# GD32A72_A74x register map
File version: 1.0
CPU: CM7 r2p1, little endian, MPU, FPU, DSP, 4 interrupt priority bits
Registers are 32-bit, read-write, reset 0x0 unless marked. A register's access mark holds for its fields unless they carry their own. Offsets are from the block's base; [hi:lo] are bit positions; {n}, {i} and the like mark numbered series; 'fields as' and 'values as' point back to an identical list.

## GPIOA — General-purpose and alternate-function I/Os
Base 0x48000000
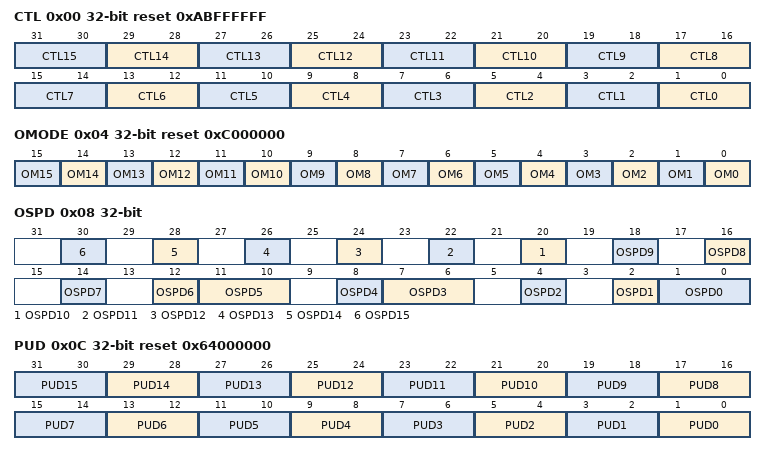
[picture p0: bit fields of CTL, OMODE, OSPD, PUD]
0x00 CTL reset 0xABFFFFFF — Port control register
  [2n+1:2n] CTL{n} (n=0..15) — Pin {n} configuration bits
0x04 OMODE reset 0xC000000 — Port output mode register
  [n] OM{n} (n=0..15) — Pin {n} output mode bit
0x08 OSPD — Port output speed register
  [2n] OSPD{n} (n=6..15) — Pin {n} output max speed bits
  [11:10] OSPD5 — Pin 5 output max speed bits
  [8] OSPD4 — Pin 4 output max speed bits
  [7:6] OSPD3 — Pin 3 output max speed bits
  [4] OSPD2 — Pin 2 output max speed bits
  [2] OSPD1 — Pin 1 output max speed bits
  [1:0] OSPD0 — Pin 0 output max speed bits
0x0C PUD reset 0x64000000 — Port pull-up / down register
  [2n+1:2n] PUD{n} (n=0..15) — Pin {n} pull-up or pull-down bits
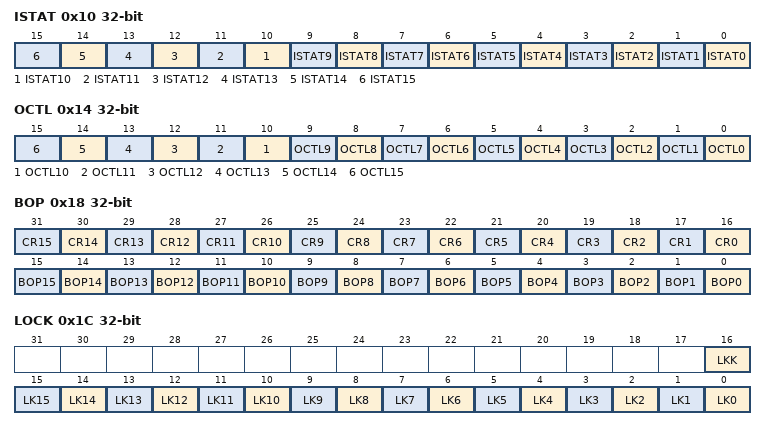
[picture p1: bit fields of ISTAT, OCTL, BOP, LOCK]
0x10 ISTAT ro — Port input status register
  [n] ISTAT{n} (n=0..15) — Port input status {n}
0x14 OCTL — Port output control register
  [n] OCTL{n} (n=0..15) — Port output control {n}
0x18 BOP wo — Port bit operate register
  [n+16] CR{n} (n=0..15) — Port clear bit {n}
  [n] BOP{n} (n=0..15) — Port set bit {n}
0x1C LOCK — Port configuration lock register
  [16] LKK — Lock key
  [15] LK15 — LOCK key writing sequence:
  [n] LK{n} (n=0..14) — Port lock bit {n+1}
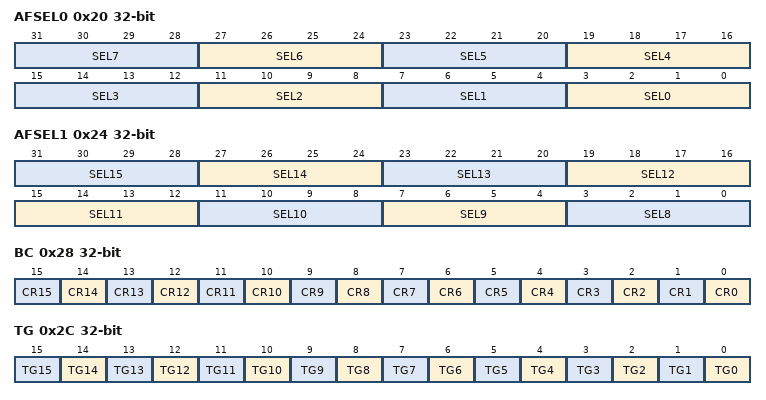
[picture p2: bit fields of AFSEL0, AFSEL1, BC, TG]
0x20 AFSEL0 — Alternate function selected register 0
  [4n+3:4n] SEL{n} (n=0..7) — Pin {n} alternate function selected
0x24 AFSEL1 — Alternate function selected register 1
  [4n-29:4n-32] SEL{n} (n=12..15) — Pin {n} alternate function selected
  [15:12] SEL11 — Pin 1 alternate function selected
  [11:8] SEL10 — Pin 10 alternate function selected
  [7:4] SEL9 — Pin 9 alternate function selected
  [3:0] SEL8 — Pin 8 alternate function selected
0x28 BC wo — Bit clear register
  [n] CR{n} (n=0..15) — Port clear bit {n}
0x2C TG wo — Port bit toggle register
  [n] TG{n} (n=0..15) — Port toggle bit {n}
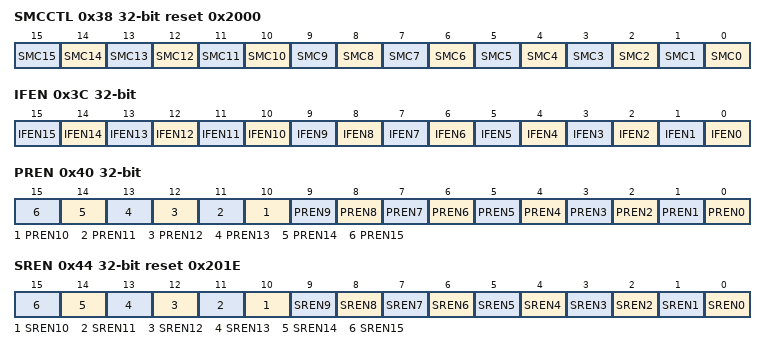
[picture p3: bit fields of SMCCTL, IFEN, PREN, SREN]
0x38 SMCCTL reset 0x2000 — Port safe mode control register
  [n] SMC{n} (n=0..15) — Pin {n} safe mode control
0x3C IFEN — Port filtering enable register
  [n] IFEN{n} (n=0..15) — Pin {n} input filter enable bit {n}
0x40 PREN — Port retain enable register
  [n] PREN{n} (n=0..15) — Pin {n} pad retain enable
0x44 SREN reset 0x201E — Port slew rate enable register
  [n] SREN{n} (n=0..15) — Pin {n} slew rate enable
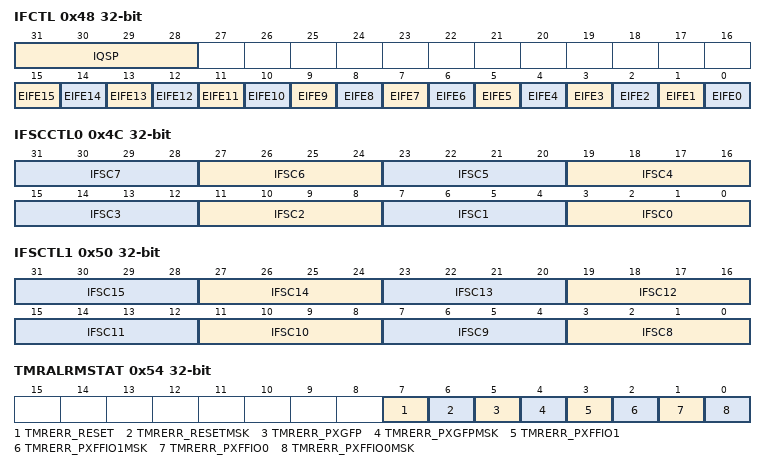
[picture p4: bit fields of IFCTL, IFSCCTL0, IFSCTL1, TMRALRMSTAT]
0x48 IFCTL — Interrupt filtering control Register
  [31:28] IQSP — External interrupt qualification sampling period for PIN0 to PIN15:
  [n] EIFE{n} (n=0..15) — Pin {n} enables digital glitch filter on the interrupt pad input
0x4C IFSCCTL0 — Interrupt filtering sample counter control register 0
  [4n+3:4n] IFSC{n} (n=0..7) — Pin{n} maximum interrupt filter counter setting
0x50 IFSCTL1 — Interrupt filtering sample counter control register 1
  [4n-29:4n-32] IFSC{n} (n=8..15) — Pin{n} maximum interrupt filter counter setting
0x54 TMRALRMSTAT — TMR alarm status register
  [7] TMRERR_RESET — RESET port mode configuration TMR error alarm
  [6] TMRERR_RESETMSK — RESET port mode configuration TMR error alarm mask
  [5] TMRERR_PXGFP — GPF port mode configuration TMR error alarm
  [4] TMRERR_PXGFPMSK — GPF port mode configuration TMR alarm error mask
  [3] TMRERR_PXFFIO1 — FFP1 port mode configuration TMR error alarm
  [2] TMRERR_PXFFIO1MSK — FFP1 port mode configuration TMR alarm error mask
  [1] TMRERR_PXFFIO0 — FFP0 port mode configuration TMR error alarm
  [0] TMRERR_PXFFIO0MSK — FFP0 port mode configuration TMR alarm mask

## GPIOB — General-purpose and alternate-function I/Os
Base 0x48000400
Registers as GPIOA; these are added or differ:
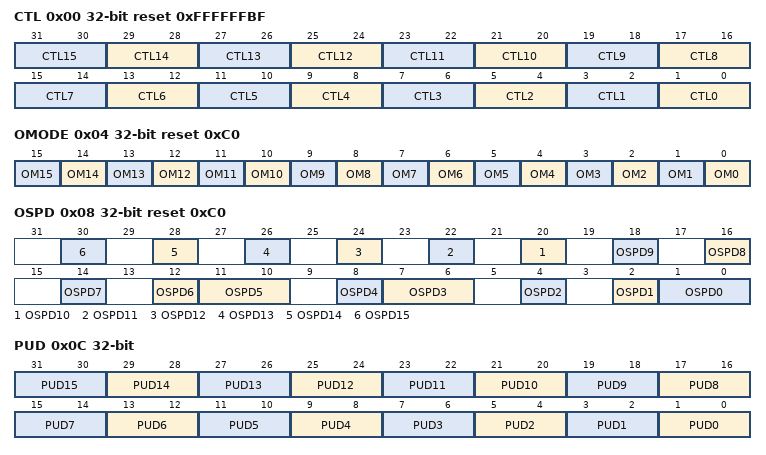
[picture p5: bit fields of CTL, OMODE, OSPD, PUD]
0x00 CTL reset 0xFFFFFFBF — Port control register
  [2n+1:2n] CTL{n} (n=0..15) — Pin {n} configuration bits
0x04 OMODE reset 0xC0 — Port output mode register
  [n] OM{n} (n=0..15) — Pin {n} output mode bit
0x08 OSPD reset 0xC0 — Port output speed register
  fields as GPIOA.OSPD
0x0C PUD — Port pull-up / down register
  [2n+1:2n] PUD{n} (n=0..15) — Pin {n} pull-up or pull-down bits
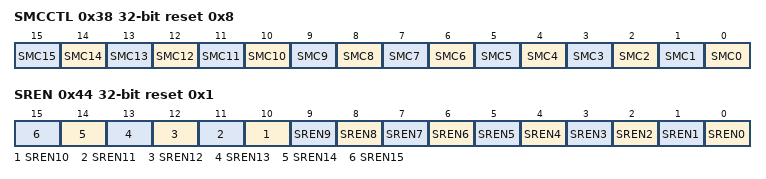
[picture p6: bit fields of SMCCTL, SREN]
0x38 SMCCTL reset 0x8 — Port safe mode control register
  [n] SMC{n} (n=0..15) — Pin {n} safe mode control
0x44 SREN reset 0x1 — Port slew rate enable register
  [n] SREN{n} (n=0..15) — Pin {n} slew rate enable

## GPIOC — General-purpose and alternate-function I/Os
Base 0x48000800
Registers as GPIOA; these are added or differ:
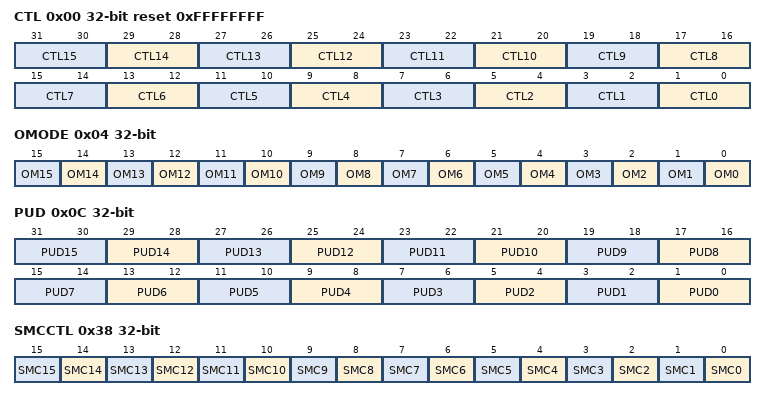
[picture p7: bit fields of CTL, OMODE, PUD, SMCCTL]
0x00 CTL reset 0xFFFFFFFF — Port control register
  [2n+1:2n] CTL{n} (n=0..15) — Pin {n} configuration bits
0x04 OMODE — Port output mode register
  [n] OM{n} (n=0..15) — Pin {n} output mode bit
0x0C PUD — Port pull-up / down register
  [2n+1:2n] PUD{n} (n=0..15) — Pin {n} pull-up or pull-down bits
0x38 SMCCTL — Port safe mode control register
  [n] SMC{n} (n=0..15) — Pin {n} safe mode control
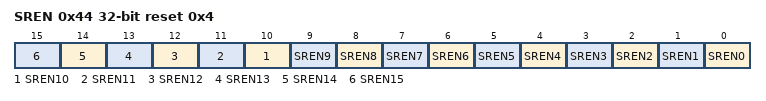
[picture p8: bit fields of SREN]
0x44 SREN reset 0x4 — Port slew rate enable register
  [n] SREN{n} (n=0..15) — Pin {n} slew rate enable

## GPIOD — General-purpose and alternate-function I/Os
Base 0x48000C00
Registers as GPIOC; these are added or differ:
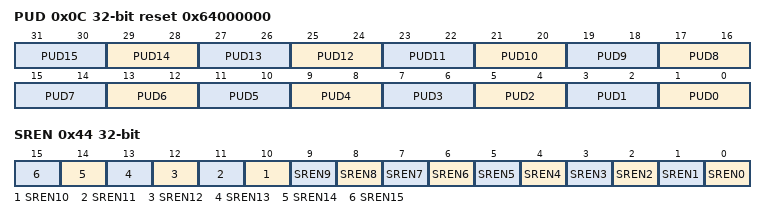
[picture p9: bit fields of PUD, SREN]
0x0C PUD reset 0x64000000 — Port pull-up / down register
  [2n+1:2n] PUD{n} (n=0..15) — Pin {n} pull-up or pull-down bits
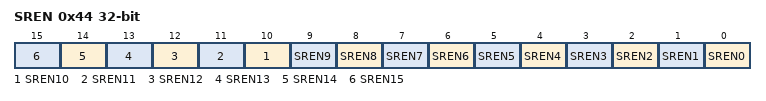
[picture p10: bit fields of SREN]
0x44 SREN — Port slew rate enable register
  [n] SREN{n} (n=0..15) — Pin {n} slew rate enable

## GPIOE — General-purpose and alternate-function I/Os
Base 0x48001000
Same registers: GPIOF 0x48001400, GPIOG 0x48001800, GPIOH 0x48001C00, GPIOI 0x48002000, GPIOJ 0x48002400, GPIOK 0x48002800, GPIOL 0x48002C00, GPIOM 0x48003000, GPION 0x48003400
Registers as GPIOC; these are added or differ:
0x44 SREN — Port slew rate enable register
  [n] SREN{n} (n=0..15) — Pin {n} slew rate enable
